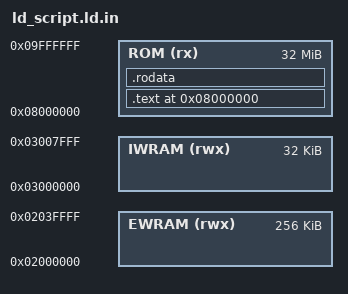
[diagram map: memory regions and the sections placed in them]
OUTPUT_ARCH(arm)
ENTRY(Start)

MEMORY
{
    EWRAM (rwx) : ORIGIN = 0x02000000, LENGTH = 256K
    IWRAM (rwx) : ORIGIN = 0x03000000, LENGTH = 32K
    ROM (rx)    : ORIGIN = 0x08000000, LENGTH = 32M
}

INCLUDE sym_ram.ld

SECTIONS
{
    . = 0x08000000;

    .text :
    ALIGN(4)
    {
        /* LINK_ORDER_TEXT */
    } > ROM =0

    .rodata :
    ALIGN(4)
    {
        build/data/rodata.o(.rodata);
    } > ROM =0

    /* Discard everything not specifically mentioned above. */
    /DISCARD/ :
    {
        *(*);
    }
}
